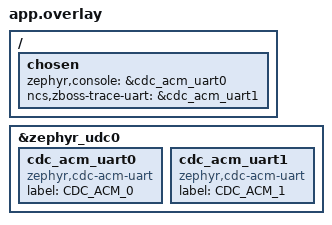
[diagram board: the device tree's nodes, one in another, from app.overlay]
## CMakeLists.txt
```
# SPDX-License-Identifier: Apache-2.0

cmake_minimum_required(VERSION 3.20.0)
find_package(Zephyr REQUIRED HINTS $ENV{ZEPHYR_BASE})
project(ultrasound-distance)

target_sources(app PRIVATE
    # Application sources
    src/main.c)

target_include_directories(app PRIVATE include)
```

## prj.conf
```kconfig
#
# Copyright (c) 2021 Nordic Semiconductor ASA
#
# SPDX-License-Identifier: LicenseRef-Nordic-5-Clause
#

#CONFIG_NCS_SAMPLES_DEFAULTS=y
#CONFIG_UART_INTERRUPT_DRIVEN=y
# Enable DK LED and Buttons library
#CONFIG_DK_LIBRARY=y


#
# Zigbee
#

CONFIG_ZIGBEE=y
CONFIG_ZIGBEE_APP_UTILS=y
CONFIG_ZIGBEE_ROLE_END_DEVICE=y

#
# Logging
#

#CONFIG_USB_DEVICE_PRODUCT="MyNRF52840Stick"
#CONFIG_USB_DEVICE_VID=4440

# PrintK

CONFIG_SERIAL=y
CONFIG_USB_DEVICE_STACK=y
CONFIG_USB_CDC_ACM=y
CONFIG_USB_CDC_ACM_LOG_LEVEL_DBG=y
CONFIG_CONSOLE=y
CONFIG_UART_CONSOLE=y                  # use one UART for console
CONFIG_UART_LINE_CTRL=y                # control serial: baud rate, etc.
CONFIG_PRINTK=y                        # send printk to console

# Traceback

#CONFIG_UART_ON_DEV_NAME="CDC_ACM_0"

#CONFIG_LOG=y                           # compile in LOG_x calls
#CONFIG_LOG_BACKEND_UART=y              # use UART for LOG_x
#CONFIG_LOG_BACKEND_SHOW_COLOR=n

#CONFIG_ZIGBEE_ENABLE_TRACES=y
#CONFIG_ZBOSS_TRACE_UART_LOGGING=y
#CONFIG_ZBOSS_TRACE_USB_CDC_LOGGING=y
#CONFIG_ZBOSS_TRACE_LOG_LEVEL_DBG=y
#CONFIG_USB_COMPOSITE_DEVICE=y

#CONFIG_LOG=y
#CONFIG_ZIGBEE_ENABLE_TRACES=y             # enable builtin traces lib
#CONFIG_ZBOSS_TRACE_UART_LOGGING=y
#CONFIG_ZIGBEE_LOGGER_EP_LOG_LEVEL_DBG=y
#CONFIG_ZBOSS_TRACE_MASK=0x0003
#CONFIG_ZBOSS_TRACE_USB_CDC_LOGGING=y
#CONFIG_ZBOSS_TRACE_LOG_LEVEL_OFF=n
#CONFIG_ZBOSS_TRACE_LOG_LEVEL_DBG=y
#CONFIG_USB_COMPOSITE_DEVICE=y             # multiple USB for serials
#CONFIG_ZBOSS_TRACE_HEXDUMP_LOGGING=y
#CONFIG_ZBOSS_TRACE_LOGGER_DEVICE_NAME="CDC_ACM_1"

# https://devzone.nordicsemi.com/f/nordic-q-a/85395/nrf52840-dongle-zephyr-logging-cdc-acm-composite
#CONFIG_LOG=y
#CONFIG_LOG_BACKEND_UART=y

#
# Other from upstream
#

CONFIG_GPIO=y
CONFIG_HEAP_MEM_POOL_SIZE=2048
CONFIG_MAIN_THREAD_PRIORITY=7


# This example requires more workqueue stack
CONFIG_SYSTEM_WORKQUEUE_STACK_SIZE=2048

# Enable nRF ECB driver
CONFIG_CRYPTO=y
CONFIG_CRYPTO_NRF_ECB=y
CONFIG_CRYPTO_INIT_PRIORITY=80

# Networking
CONFIG_NET_IPV6_MLD=n
CONFIG_NET_IPV6_NBR_CACHE=n
CONFIG_NET_IPV6_RA_RDNSS=n
CONFIG_NET_IP_ADDR_CHECK=n
CONFIG_NET_UDP=n
```

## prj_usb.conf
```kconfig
CONFIG_ZIGBEE_UART_DEVICE_NAME="CDC_ACM_0"
CONFIG_ZIGBEE_UART_SUPPORTS_FLOW_CONTROL=y
CONFIG_USB_COMPOSITE_DEVICE=y

CONFIG_USB_DEVICE_STACK=y
CONFIG_USB_DEVICE_REMOTE_WAKEUP=n
CONFIG_USB_DEVICE_PRODUCT="Zigbee NCP"
CONFIG_USB_CDC_ACM=y
CONFIG_UART_LINE_CTRL=y

CONFIG_ZIGBEE=y

CONFIG_ZIGBEE_LIBRARY_NCP_DEV=y

CONFIG_ZIGBEE_HAVE_SERIAL=y
CONFIG_ZIGBEE_HAVE_ASYNC_SERIAL=y
CONFIG_ZIGBEE_UART_RX_BUF_LEN=256
CONFIG_ZIGBEE_UART_TX_TIMEOUT=1000
CONFIG_ZIGBEE_UART_RX_TIMEOUT=1000

CONFIG_ZIGBEE_USE_LEDS=y
CONFIG_ZIGBEE_TIME_KTIMER=y
CONFIG_ZIGBEE_ROLE_COORDINATOR=y

CONFIG_HEAP_MEM_POOL_SIZE=2048

CONFIG_MAIN_THREAD_PRIORITY=7

CONFIG_SYSTEM_WORKQUEUE_STACK_SIZE=2048

# NetworkingCONFIG_NET_IPV6_MLD=n
CONFIG_NET_IPV6_NBR_CACHE=n
CONFIG_NET_IPV6_RA_RDNSS=n
CONFIG_NET_IP_ADDR_CHECK=n
CONFIG_NET_UDP=n

CONFIG_LOG=y
CONFIG_LOG_DEFAULT_LEVEL=3
CONFIG_CONSOLE=y
CONFIG_UART_CONSOLE=y
CONFIG_LOG_BACKEND_UART=y

CONFIG_ASSERT=nCONFIG_ASSERT_NO_COND_INFO=n
CONFIG_ASSERT_NO_MSG_INFO=n
```

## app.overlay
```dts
/*
 * Copyright (c) 2022 Brandon Satrom
 *
 * SPDX-License-Identifier: Apache-2.0
 */

/ {
	chosen {
		zephyr,console = &cdc_acm_uart0;
		ncs,zboss-trace-uart = &cdc_acm_uart1;
	};
};

&zephyr_udc0 {
	cdc_acm_uart0: cdc_acm_uart0 {
		compatible = "zephyr,cdc-acm-uart";
		label = "CDC_ACM_0";
	};
	cdc_acm_uart1: cdc_acm_uart1 {
		compatible = "zephyr,cdc-acm-uart";
		label = "CDC_ACM_1";
	};
};
```

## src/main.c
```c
/*
 * Written by Brandon Satrom.
 *
 * Copyright (c) 2022 Blues Inc. MIT License. Use of this source code is
 * governed by licenses granted by the copyright holder including that found in
 * the LICENSE file.
 */

#include <sys/printk.h>
#include <sys/util.h>
#include <string.h>

#include <usb/usb_device.h>
#include <drivers/uart.h>

#include <zephyr/drivers/gpio.h>
#include <zephyr/logging/log.h>
#include <zephyr/settings/settings.h>

#include <zboss_api.h>
#include <zboss_api_addons.h>
#include <zigbee/zigbee_app_utils.h>
#include <zigbee/zigbee_error_handler.h>
#include <zigbee/zigbee_zcl_scenes.h>
#include <zb_nrf_platform.h>

#include "my_zb_zcl_analog_input.h"
#include "zb_ultrasound_distance.h"

// Edited remotely

LOG_MODULE_REGISTER(zigmee, LOG_LEVEL_DBG);

/*
 * Ensure that an overlay for USB serial has been defined.
 */
BUILD_ASSERT(DT_NODE_HAS_COMPAT(DT_CHOSEN(zephyr_console), zephyr_cdc_acm_uart),
	    "Console device is not ACM CDC UART device");

/*
 * Defines
 */

#define ZB_ZCL_MIN_REPORTING_INTERVAL_DEFAULT 0x05
#define ZIGBEE_NETWORK_STATE_LED 0
#define LED0 DT_ALIAS(led0)
/* Device endpoint, used to receive ZCL commands. */
#define ULTRASOUND_DISTANCE_ENDPOINT 1
static const struct gpio_dt_spec led = GPIO_DT_SPEC_GET(LED0, gpios);

/* ESP tutorial */
#define IEEE_CHANNEL_MASK (1l << 13)  // channel 13
#define ERASE_PERSISTENT_CONFIG ZB_TRUE
/* END ESP tutorial */

/*
 * Zigbee setup
 */

/* Main application customizable context.
 * Stores all settings and static values.
 */

// ===== Declare Structures =====

typedef struct {
	zb_uint32_t present_value;
	zb_bool_t out_of_service;
	zb_uint8_t status_flags;
} my_zb_zcl_analog_input_basic_attrs;

typedef struct {
	zb_zcl_basic_attrs_ext_t basic_attr;
	zb_zcl_identify_attrs_t identify_attr;
	zb_zcl_scenes_attrs_t scenes_attr;
	zb_zcl_groups_attrs_t groups_attr;
	my_zb_zcl_analog_input_basic_attrs analog_input_attr;
} zb_device_ctx;

static zb_device_ctx dev_ctx;

// ===== Declare Attributes =====

ZB_ZCL_DECLARE_BASIC_ATTRIB_LIST_EXT(basic_attr_list,
	&dev_ctx.basic_attr.zcl_version,
	&dev_ctx.basic_attr.app_version,
	&dev_ctx.basic_attr.stack_version,
	&dev_ctx.basic_attr.hw_version,
	&dev_ctx.basic_attr.mf_name,
	&dev_ctx.basic_attr.model_id,
	&dev_ctx.basic_attr.date_code,
	&dev_ctx.basic_attr.location_id,
	&dev_ctx.basic_attr.ph_env,
	&dev_ctx.basic_attr.sw_ver,
	&dev_ctx.basic_attr.power_source);

ZB_ZCL_DECLARE_IDENTIFY_ATTRIB_LIST(identify_attr_list,
	&dev_ctx.identify_attr.identify_time);

ZB_ZCL_DECLARE_GROUPS_ATTRIB_LIST(groups_attr_list,
	&dev_ctx.groups_attr.name_support);

ZB_ZCL_DECLARE_SCENES_ATTRIB_LIST(scenes_attr_list,
	&dev_ctx.scenes_attr.scene_count,
	&dev_ctx.scenes_attr.current_scene,
	&dev_ctx.scenes_attr.current_group,
	&dev_ctx.scenes_attr.scene_valid,
	&dev_ctx.scenes_attr.name_support);
	
ZB_ZCL_DECLARE_ANALOG_INPUT_ATTRIB_LIST(analog_input_attr_list,
    &dev_ctx.analog_input_attr.out_of_service,
    &dev_ctx.analog_input_attr.present_value,
    &dev_ctx.analog_input_attr.status_flags);

// ===== Declare Device =====

ZB_DECLARE_ULTRASOUND_DISTANCE_CLUSTER_LIST(ultrasound_distance_clusters,
	basic_attr_list,
	identify_attr_list,
    groups_attr_list,
    scenes_attr_list,
	analog_input_attr_list);

ZB_DECLARE_ULTRASOUND_DISTANCE_EP(
	ultrasound_distance_ep,
	ULTRASOUND_DISTANCE_ENDPOINT,
	ultrasound_distance_clusters);
	

ZBOSS_DECLARE_DEVICE_CTX_1_EP(ultrasound_distance_ctx,
	ultrasound_distance_ep);

// ===== Business functions =====

static void init_zigbee_cluster_attributes() {
	// "Basic" cluster attributes
	dev_ctx.basic_attr.zcl_version = ZB_ZCL_VERSION;
	dev_ctx.basic_attr.power_source = ZB_ZCL_BASIC_POWER_SOURCE_BATTERY;
	ZB_ZCL_SET_STRING_VAL(
		dev_ctx.basic_attr.mf_name,
		"Tanel Liiv",
		ZB_ZCL_STRING_CONST_SIZE("Tanel Liiv"));
	ZB_ZCL_SET_STRING_VAL(
		dev_ctx.basic_attr.model_id,
		"tliiv.ultrasound_distance",
		ZB_ZCL_STRING_CONST_SIZE("tliiv.ultrasound_distance"));

	// "Identify" cluster attributes
	dev_ctx.identify_attr.identify_time = ZB_ZCL_IDENTIFY_IDENTIFY_TIME_DEFAULT_VALUE;

	// Groups cluster attribs
	dev_ctx.groups_attr.name_support = 0;

	// Scenes cluster attribs
	dev_ctx.scenes_attr.name_support = 0;

	// Distance attributes
	dev_ctx.analog_input_attr.out_of_service = false;
	dev_ctx.analog_input_attr.present_value = 123.0;
	dev_ctx.analog_input_attr.status_flags = 0;
}

static void start_identifying() {
	if (ZB_JOINED()) {
		zb_ret_t zb_err_code = zb_bdb_finding_binding_target(
			ULTRASOUND_DISTANCE_ENDPOINT
		);	
		if (zb_err_code == RET_OK) {
			printk("Entered identify mode!\n");
		} else if (zb_err_code == RET_INVALID_STATE) {
			printk("Invalid state!\n");	
		} else {
			printk("Umm, something else\n");
		}
	} else {
		printk("Device not in a network, cannot identify\n");
	}
}

/*
 * @brief Function to handle identify notification events on the first endpoint.
 * @param  bufid  Unused parameter, required by ZBOSS scheduler API.
 */
static void identify_cb(zb_bufid_t bufid)
{
	printk("IdentityCB!\n");
	k_sleep(K_MSEC(1000));

	zb_ret_t zb_err_code;
	if (bufid) {
		// Schedule a self-scheduling function that will toggle the LED
		//ZB_SCHEDULE_APP_CALLBACK(toggle_identify_led, bufid);
	} else {
		// Cancel the toggling function alarm and turn off LED
		//zb_err_code = ZB_SCHEDULE_APP_ALARM_CANCEL(toggle_identify_led, ZB_ALARM_ANY_PARAM);
		ZVUNUSED(zb_err_code);
		//dk_set_led(IDENTIFY_LED, 0);
	}
}

static void zcl_device_cb(zb_bufid_t bufid) {
	printk("DEVICE_DB\n");
}

void zboss_signal_handler(zb_bufid_t bufid) {
    ZB_ERROR_CHECK(zigbee_default_signal_handler(bufid));
    if (bufid) {
        zb_buf_free(bufid);
    }
}

void zboss_signal_handler2(zb_bufid_t bufid) {

	// update network status led
	//zigbee_led_status_update(bufid, ZIGBEE_NETWORK_STATE_LED);

	// No application-specific behavior is required. Call default signal handler.
	//zigbee_default_signal_handler(bufid);
	
	zb_zdo_app_signal_hdr_t *hdr = NULL;
	zb_zdo_app_signal_type_t sig = zb_get_app_signal(bufid, &hdr);
	zb_ret_t              status = ZB_GET_APP_SIGNAL_STATUS(bufid);

	if (sig != ZB_COMMON_SIGNAL_CAN_SLEEP) {
		printk("ZBOSS_SIGNAL_HANDLER signal %d status %d\n", sig, status);
	}

	switch (sig){
    case ZB_ZDO_SIGNAL_PRODUCTION_CONFIG_READY:
        printk("App config loaded: %d\n", status == RET_OK);
        break;
	case ZB_ZDO_SIGNAL_SKIP_STARTUP:
		printk("Zigbee stack init: %d\n", status == RET_OK);
		bdb_start_top_level_commissioning(ZB_BDB_INITIALIZATION);
		break;
	case ZB_BDB_SIGNAL_DEVICE_FIRST_START:
        printk("Started first time after NVRAM erase: %d\n", status == RET_OK);
		if (status == RET_OK) {
			printk("Start network steering\n");
			bdb_start_top_level_commissioning(ZB_BDB_NETWORK_STEERING);
		} else {
			printk("Failed to init Zigbee stack\n");
		}
		break;
	case ZB_BDB_SIGNAL_STEERING:
        printk("Network steering: %d\n", status == RET_OK);
		if (status == RET_OK) {
			printk("Joined network!\n");
		} else {
			printk("Steering unsuccessful :(\n");
			ZB_SCHEDULE_APP_ALARM((zb_callback_t) bdb_start_top_level_commissioning,
					ZB_BDB_NETWORK_STEERING, ZB_TIME_ONE_SECOND);
		}
		break;
	case ZB_BDB_SIGNAL_DEVICE_REBOOT:
		printk("Re/Joined a network using NVRAM contents\n");
        zb_ret_t resp = zb_zcl_start_attr_reporting(
                ULTRASOUND_DISTANCE_ENDPOINT,
                ZB_ZCL_CLUSTER_ID_ANALOG_INPUT,
                ZB_ZCL_CLUSTER_SERVER_ROLE,
                ZB_ZCL_ATTR_ANALOG_INPUT_PRESENT_VALUE_ID);
        if (resp == RET_OK) {
            printk("Reporting started!\n");
        } else {
            printk("Reporting failed to start\n");
        }
		break;
	case ZB_COMMON_SIGNAL_CAN_SLEEP:
		break;
	default:
		// print the unknown signal value
		printk("Unhandled signal: %d\n", sig);
		break;
	}

	k_sleep(K_MSEC(333));

	/* All callbacks should either reuse or free passed buffers.
	 * If bufid == 0, the buffer is invalid (not passed).
	 */
	if (bufid) {
		zb_buf_free(bufid);
	}
}

/*
 * None Zigbee stuff
 */

void zigbee_setup() {
	// -- Zigbee Stack
	
	/*ZB_INIT("avalanche_duck");
	zb_set_network_ed_role(IEEE_CHANNEL_MASK);
	zb_set_nvram_erase_at_start(ERASE_PERSISTENT_CONFIG);
	zb_set_ed_timeout(ED_AGING_TIMEOUT_64MIN);
	zb_set_keepalive_timeout(ZB_MILLISECONDS_TO_BEACON_INTERVAL(3000));*/

	zb_set_network_ed_role(ZB_TRANSCEIVER_ALL_CHANNELS_MASK);
	// -- HW Related

	ZB_ZCL_REGISTER_DEVICE_CB(zcl_device_cb);
	ZB_AF_REGISTER_DEVICE_CTX(&ultrasound_distance_ctx);

	// set all initial values
	init_zigbee_cluster_attributes();

	ZB_AF_SET_IDENTIFY_NOTIFICATION_HANDLER(ULTRASOUND_DISTANCE_ENDPOINT, identify_cb);
}

static zb_uint32_t i = 0;
void measure_distance() {
    //if (!system_param.connected) return;
    // -- Measure distance
    printk("Measure distance %d\n", ++i);
    // integer to bytes
    float distance = (float)i;
    zb_uint8_t *bytes = (zb_uint8_t *) &distance;

    zb_zcl_status_t result = zb_zcl_set_attr_val(
        ULTRASOUND_DISTANCE_ENDPOINT,
        ZB_ZCL_CLUSTER_ID_ANALOG_INPUT,
        ZB_ZCL_CLUSTER_SERVER_ROLE,
        ZB_ZCL_ATTR_ANALOG_INPUT_PRESENT_VALUE_ID,
        bytes,
        ZB_FALSE
    );
    if (result != ZB_ZCL_STATUS_SUCCESS) {
        printk("Failed to set attribute value: %d\n", result);
    }
    zb_zcl_mark_attr_for_reporting(
        ULTRASOUND_DISTANCE_ENDPOINT,
        ZB_ZCL_CLUSTER_ID_ANALOG_INPUT,
        ZB_ZCL_CLUSTER_SERVER_ROLE,
        ZB_ZCL_ATTR_ANALOG_INPUT_PRESENT_VALUE_ID
    );
    /*
    zb_bool_t resp = zcl_is_attr_reported(
            ULTRASOUND_DISTANCE_ENDPOINT,
            ZB_ZCL_CLUSTER_ID_ANALOG_INPUT,
            ZB_ZCL_CLUSTER_SERVER_ROLE,
            ZB_ZCL_ATTR_ANALOG_INPUT_PRESENT_VALUE_ID);
    if (resp) {
        printk("Attribute is reported\n");
    } else {
        printk("Attribute is not reported\n");
    }*/

}

void start_reporting() {
    zb_ret_t resp = zb_zcl_start_attr_reporting(
            ULTRASOUND_DISTANCE_ENDPOINT,
            ZB_ZCL_CLUSTER_ID_ANALOG_INPUT,
            ZB_ZCL_CLUSTER_SERVER_ROLE,
            ZB_ZCL_ATTR_ANALOG_INPUT_PRESENT_VALUE_ID);

    if (resp == RET_OK) {
        printk("Reporting started!\n");
    } else {
        printk("Reporting failed to start\n");
    }
}

void main(void)
{
	gpio_pin_configure_dt(&led, GPIO_OUTPUT_ACTIVE);

	/* Set ZigBee stack logging level and traffic dump subsystem. */
	//ZB_SET_TRACE_LEVEL(0b111111);
	//ZB_SET_TRACE_MASK(ZIGBEE_TRACE_MASK);
	//ZB_SET_TRAF_DUMP_OFF();

	// --- Configure USB Serial for Console output ---


	const struct device *usb_dev = DEVICE_DT_GET(DT_CHOSEN(zephyr_console));
	uint32_t dtr = 0;

	if (usb_enable(NULL)) {
		return;
	}

	uint32_t i = 0;
	while (!dtr) {
		uart_line_ctrl_get(usb_dev, UART_LINE_CTRL_DTR, &dtr);
		gpio_pin_set_raw(led.port, led.pin, i++ % 10 > 0 ? 0 : 1);
		k_sleep(K_MSEC(200));
	}

	//zcl_scenes_init();
	/*int err = settings_subsys_init();
	if (err) {
		printk("Failed to init settings!\n");
	}*/

	// --- Start ---

	printk("=| Welcome to Avalanche Duck NRF52840 Zigbee Endpoint v0.1|=\n");
	LOG_ERR("HI LOG WORKS!\n");

	zigbee_setup();
	zigbee_enable();
    start_reporting();

	i = 1;
	while (1) {
		gpio_pin_set_raw(led.port, led.pin, i % 2);
        printk("Main loop %d\n", i++);
		if (i % 10 == 0) {
            //zboss_main_loop_iteration();
            printk("measuring\n");
            measure_distance();
		}
		k_sleep(K_MSEC(1000));
	}
}
```

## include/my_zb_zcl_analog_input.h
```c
/*
 * ZBOSS Zigbee 3.0
 *
 * Copyright (c) 2012-2022 DSR Corporation, Denver CO, USA.
 * www.dsr-zboss.com
 * www.dsr-corporation.com
 * All rights reserved.
 *
 *
 * Use in source and binary forms, redistribution in binary form only, with
 * or without modification, are permitted provided that the following conditions
 * are met:
 *
 * 1. Redistributions in binary form, except as embedded into a Nordic
 *    Semiconductor ASA integrated circuit in a product or a software update for
 *    such product, must reproduce the above copyright notice, this list of
 *    conditions and the following disclaimer in the documentation and/or other
 *    materials provided with the distribution.
 *
 * 2. Neither the name of Nordic Semiconductor ASA nor the names of its
 *    contributors may be used to endorse or promote products derived from this
 *    software without specific prior written permission.
 *
 * 3. This software, with or without modification, must only be used with a Nordic
 *    Semiconductor ASA integrated circuit.
 *
 * 4. Any software provided in binary form under this license must not be reverse
 *    engineered, decompiled, modified and/or disassembled.
 *
 * THIS SOFTWARE IS PROVIDED BY NORDIC SEMICONDUCTOR ASA "AS IS" AND ANY EXPRESS OR
 * IMPLIED WARRANTIES, INCLUDING, BUT NOT LIMITED TO, THE IMPLIED WARRANTIES OF
 * MERCHANTABILITY, NONINFRINGEMENT, AND FITNESS FOR A PARTICULAR PURPOSE ARE
 * DISCLAIMED. IN NO EVENT SHALL NORDIC SEMICONDUCTOR ASA OR CONTRIBUTORS BE LIABLE
 * FOR ANY DIRECT, INDIRECT, INCIDENTAL, SPECIAL, EXEMPLARY, OR CONSEQUENTIAL
 * DAMAGES (INCLUDING, BUT NOT LIMITED TO, PROCUREMENT OF SUBSTITUTE GOODS OR
 * SERVICES; LOSS OF USE, DATA, OR PROFITS; OR BUSINESS INTERRUPTION) HOWEVER
 * CAUSED AND ON ANY THEORY OF LIABILITY, WHETHER IN CONTRACT, STRICT LIABILITY, OR
 * TORT (INCLUDING NEGLIGENCE OR OTHERWISE) ARISING IN ANY WAY OUT OF THE USE OF
 * THIS SOFTWARE, EVEN IF ADVISED OF THE POSSIBILITY OF SUCH DAMAGE.
 */
/* PURPOSE: (Incomplete!) Analog Output cluster
 * By Tanel Liiv
*/

#ifndef ZB_ZCL_ANALOG_INPUT_H
#define ZB_ZCL_ANALOG_INPUT_H 1

#include "zcl/zb_zcl_common.h"
#include "zcl/zb_zcl_commands.h"

enum zb_zcl_analog_input_attr_e
{
  /** The Description attribute, of type Character string, MAY be used to hold a
   *  description of the usage of the input, output or value, as appropriate
   *  to the cluster. */
  ZB_ZCL_ATTR_ANALOG_INPUT_DESCRIPTION_ID               = 0x001C,
  /** This attribute, of type Character string, MAY be used to hold a human readable
   *  description of the INACTIVE state of a binary PresentValue. */
  ZB_ZCL_ATTR_ANALOG_INPUT_INACTIVE_TEXT_ID             = 0x002E,

  /** @brief OutOfService attribute */
  ZB_ZCL_ATTR_ANALOG_INPUT_OUT_OF_SERVICE_ID            = 0x0051,

  /** @brief PresentValue attribute */
  ZB_ZCL_ATTR_ANALOG_INPUT_PRESENT_VALUE_ID             = 0x0055,

  /** @brief StatusFlag attribute */
  ZB_ZCL_ATTR_ANALOG_INPUT_STATUS_FLAG_ID               = 0x006F,
};

/**
 *  @brief StatusFlag attribute values.
 *  @see ZCL spec 3.14.10.3.
 */
enum zb_zcl_analog_input_status_flag_value_e
{
  ZB_ZCL_ANALOG_INPUT_STATUS_FLAG_NORMAL    = 0x00,       /**< Normal (default) state. */
  ZB_ZCL_ANALOG_INPUT_STATUS_FLAG_IN_ALARM  = 0x01,       /**< In alarm bit. */
  ZB_ZCL_ANALOG_INPUT_STATUS_FLAG_FAULT     = 0x02,       /**< Fault bit. */
  ZB_ZCL_ANALOG_INPUT_STATUS_FLAG_OVERRIDEN = 0x04,       /**< Overridden bit. */
  ZB_ZCL_ANALOG_INPUT_STATUS_FLAG_OUT_OF_SERVICE = 0x08,  /**< Out of service bit. */
};

/** @brief Default value for Binary Input cluster revision global attribute */
//#define ZB_ZCL_BINARY_INPUT_CLUSTER_REVISION_DEFAULT ((zb_uint16_t)0x0001u)
#define ZB_ZCL_ANALOG_INPUT_CLUSTER_REVISION_DEFAULT ((zb_uint16_t)0x0001u)

/** @brief Default value for ActiveText attribute */
#define ZB_ZCL_BINARY_INPUT_ACTIVE_TEXT_DEFAULT_VALUE {0}

/** @brief Default value for Description attribute */
#define ZB_ZCL_BINARY_INPUT_DESCRIPTION_DEFAULT_VALUE {0}

/** @brief Default value for InactiveText attribute */
#define ZB_ZCL_BINARY_INPUT_INACTIVE_TEXT_DEFAULT_VALUE {0}

/*! @brief OutOfService attribute default value */
#define ZB_ZCL_ANALOG_INPUT_OUT_OF_SERVICE_DEFAULT_VALUE ZB_FALSE

/** @brief Default value for Polarity attribute */
#define ZB_ZCL_BINARY_INPUT_POLARITY_DEFAULT_VALUE ((zb_uint8_t)0)

/** @brief Default value for Reliability attribute */
#define ZB_ZCL_BINARY_INPUT_RELIABILITY_DEFAULT_VALUE ((zb_uint8_t)0x00)

/*! @brief StatusFlag attribute default value */
#define ZB_ZCL_BINARY_INPUT_STATUS_FLAG_DEFAULT_VALUE ZB_ZCL_BINARY_INPUT_STATUS_FLAG_NORMAL

/*! @brief StatusFlag attribute minimum value */
#define ZB_ZCL_BINARY_INPUT_STATUS_FLAG_MIN_VALUE 0

/*! @brief StatusFlag attribute maximum value */
#define ZB_ZCL_BINARY_INPUT_STATUS_FLAG_MAX_VALUE 0x0F

/** @brief Declare attribute list for Binary Input cluster
    @param attr_list - attribute list name
    @param out_of_service - pointer to variable to store OutOfService attribute value
    @param present_value -  pointer to variable to store PresentValue attribute value
    @param status_flag -  pointer to variable to store StatusFlag attribute value
*/
#define ZB_ZCL_DECLARE_ANALOG_INPUT_ATTRIB_LIST(                                     \
    attr_list, out_of_service, present_value, status_flag)                           \
  ZB_ZCL_START_DECLARE_ATTRIB_LIST_CLUSTER_REVISION(attr_list, ZB_ZCL_ANALOG_INPUT)  \
  ZB_ZCL_SET_ATTR_DESC(ZB_ZCL_ATTR_ANALOG_INPUT_OUT_OF_SERVICE_ID, (out_of_service)) \
  ZB_ZCL_SET_ATTR_DESC(ZB_ZCL_ATTR_ANALOG_INPUT_PRESENT_VALUE_ID, (present_value))   \
  ZB_ZCL_SET_ATTR_DESC(ZB_ZCL_ATTR_ANALOG_INPUT_STATUS_FLAG_ID, (status_flag))       \
  ZB_ZCL_FINISH_DECLARE_ATTRIB_LIST

/*! @} */ /* Binary Input cluster attributes */

/*! @name Binary input attribute value manipulation API
    @{
*/

/** @brief Set normal operating mode
    @param ep - endpoint number
*/
/*
#define ZB_ZCL_BINARY_INPUT_SET_NORMAL_MODE(ep)                           \
{                                                                         \
  zb_uint8_t val;                                                         \
                                                                          \
  val = ZB_FALSE;                                                         \
  ZB_ZCL_SET_ATTRIBUTE(ep, ZB_ZCL_CLUSTER_ID_BINARY_INPUT,                \
                       ZB_ZCL_CLUSTER_SERVER_ROLE,                        \
                       ZB_ZCL_ATTR_BINARY_INPUT_OUT_OF_SERVICE_ID,        \
                       &val, ZB_FALSE);                                   \
                                                                          \
  val = ZB_ZCL_BINARY_INPUT_STATUS_FLAG_NORMAL;                           \
  ZB_ZCL_SET_ATTRIBUTE(ep, ZB_ZCL_CLUSTER_ID_BINARY_INPUT,                \
                       ZB_ZCL_CLUSTER_SERVER_ROLE,                        \
                       ZB_ZCL_ATTR_BINARY_INPUT_STATUS_FLAG_ID,           \
                       &val, ZB_FALSE);                                   \
}*/

/** @brief Set Out of service operating mode
    @param ep - endpoint number
*/
/*
#define ZB_ZCL_BINARY_INPUT_SET_OUT_OF_SERVICE(ep)                                          \
{                                                                                           \
  zb_zcl_attr_t *attr_desc;                                                                 \
  zb_uint8_t val;                                                                           \
                                                                                            \
  val = ZB_TRUE;                                                                            \
  ZB_ZCL_SET_ATTRIBUTE(ep, ZB_ZCL_CLUSTER_ID_BINARY_INPUT,                                  \
                       ZB_ZCL_CLUSTER_SERVER_ROLE,                                          \
                       ZB_ZCL_ATTR_BINARY_INPUT_OUT_OF_SERVICE_ID,                          \
                       &val, ZB_FALSE);                                                     \
                                                                                            \
  attr_desc = zb_zcl_get_attr_desc_a(ep, ZB_ZCL_CLUSTER_ID_BINARY_INPUT,                    \
                                     ZB_ZCL_CLUSTER_SERVER_ROLE,        \
                                     ZB_ZCL_ATTR_BINARY_INPUT_STATUS_FLAG_ID); \
  if (attr_desc)                                                                            \
  {                                                                                         \
    val = *(zb_uint8_t*)attr_desc->data_p | ZB_ZCL_BINARY_INPUT_STATUS_FLAG_OUT_OF_SERVICE; \
    ZB_ZCL_SET_ATTRIBUTE(ep, ZB_ZCL_CLUSTER_ID_BINARY_INPUT,                                \
                         ZB_ZCL_CLUSTER_SERVER_ROLE,                    \
                         ZB_ZCL_ATTR_BINARY_INPUT_STATUS_FLAG_ID,                           \
                         &val, ZB_FALSE);                                                   \
  }                                                                                         \
}*/

/** @brief Set overridden operating mode
   @param ep - endpoint number
*/
/*
#define ZB_ZCL_BINARY_INPUT_SET_OVERRIDEN_MODE(ep)                                     \
{                                                                                      \
  zb_zcl_attr_t *attr_desc;                                                            \
  zb_uint8_t val;                                                                      \
                                                                                       \
  attr_desc = zb_zcl_get_attr_desc_a(ep, ZB_ZCL_CLUSTER_ID_BINARY_INPUT,               \
                                     ZB_ZCL_CLUSTER_SERVER_ROLE,        \
                         ZB_ZCL_ATTR_BINARY_INPUT_STATUS_FLAG_ID);                     \
  if (attr_desc)                                                                       \
  {                                                                                    \
    val = *(zb_uint8_t*)attr_desc->data_p | ZB_ZCL_BINARY_INPUT_STATUS_FLAG_OVERRIDEN; \
    ZB_ZCL_SET_ATTRIBUTE(ep, ZB_ZCL_CLUSTER_ID_BINARY_INPUT,                           \
                         ZB_ZCL_CLUSTER_SERVER_ROLE,                    \
                         ZB_ZCL_ATTR_BINARY_INPUT_STATUS_FLAG_ID,                      \
                         &val, ZB_FALSE);                                              \
  }                                                                                    \
}*/

/*! @} */ /* Binary input cluster commands */

/** @cond internals_doc */
/** @name Binary Input cluster internals
    Internal structures for Binary Input cluster
    @{
*/

/* Optionally, access to this attribute may be changed to READ_WRITE */
#define ZB_SET_ATTR_DESCR_WITH_ZB_ZCL_ATTR_ANALOG_INPUT_OUT_OF_SERVICE_ID(data_ptr) \
{                                                                   \
  ZB_ZCL_ATTR_ANALOG_INPUT_OUT_OF_SERVICE_ID,                       \
  ZB_ZCL_ATTR_TYPE_BOOL,                                            \
  ZB_ZCL_ATTR_ACCESS_READ_ONLY | ZB_ZCL_ATTR_ACCESS_REPORTING, \
  (void*) data_ptr                                             \
}

/* Optionally, access to this attribute may be changed to READ_WRITE */
#define ZB_SET_ATTR_DESCR_WITH_ZB_ZCL_ATTR_ANALOG_INPUT_PRESENT_VALUE_ID(data_ptr) \
{                                                                   \
  ZB_ZCL_ATTR_ANALOG_INPUT_PRESENT_VALUE_ID,                        \
  ZB_ZCL_ATTR_TYPE_SINGLE,                                          \
  ZB_ZCL_ATTR_ACCESS_READ_ONLY | ZB_ZCL_ATTR_ACCESS_REPORTING, \
  (void*) data_ptr                                             \
}

#define ZB_SET_ATTR_DESCR_WITH_ZB_ZCL_ATTR_ANALOG_INPUT_STATUS_FLAG_ID(data_ptr) \
{                                                                   \
  ZB_ZCL_ATTR_ANALOG_INPUT_STATUS_FLAG_ID,                          \
  ZB_ZCL_ATTR_TYPE_8BITMAP,                                          \
  ZB_ZCL_ATTR_ACCESS_READ_ONLY | ZB_ZCL_ATTR_ACCESS_REPORTING,      \
  (void*) data_ptr                                             \
}

/*! Number of attributes mandatory for reporting in Analog Input cluster */
#define ZB_ZCL_ANALOG_INPUT_REPORT_ATTR_COUNT 3

/*! @}
 *  @endcond */ /* Binary Input cluster internals */


/*! @} */ /* ZCL Binary Input cluster definitions */

/** @endcond */ /* DOXYGEN_ZCL_SECTION */

void zb_zcl_analog_input_init_server(void);
// from zcl_binary_input.c

void zb_zcl_analog_input_init_server(void)
{
  zb_zcl_add_cluster_handlers(ZB_ZCL_CLUSTER_ID_ANALOG_INPUT,
			      ZB_ZCL_CLUSTER_SERVER_ROLE,
			      (zb_zcl_cluster_check_value_t)NULL,
			      (zb_zcl_cluster_write_attr_hook_t)NULL,
			      (zb_zcl_cluster_handler_t)NULL);
}

void zb_zcl_analog_input_init_client(void);
// from zcl_binary_input.c
void zb_zcl_analog_input_init_client(void)
{
  zb_zcl_add_cluster_handlers(ZB_ZCL_CLUSTER_ID_ANALOG_INPUT,
			      ZB_ZCL_CLUSTER_CLIENT_ROLE,
			      (zb_zcl_cluster_check_value_t)NULL,
			      (zb_zcl_cluster_write_attr_hook_t)NULL,
			      (zb_zcl_cluster_handler_t)NULL);
}

#define ZB_ZCL_CLUSTER_ID_ANALOG_INPUT_SERVER_ROLE_INIT zb_zcl_analog_input_init_server
#define ZB_ZCL_CLUSTER_ID_ANALOG_INPUT_CLIENT_ROLE_INIT zb_zcl_analog_input_init_client

#endif /* ZB_ZCL_BINARY_INPUT_H */
```

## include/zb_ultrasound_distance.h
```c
// sdk-nrf / zigbee / light_bulb / zb_dimmable_light.h
// https://github.com/nrfconnect/sdk-nrf/blob/main/samples/zigbee/light_bulb/include/zb_dimmable_light.h
// I excluded level control in last _EP

// -- Declare Cluster List

#define ZB_DECLARE_ULTRASOUND_DISTANCE_CLUSTER_LIST( \
	cluster_list_name, \
	basic_attr_list, \
	identify_attr_list, \
    groups_attr_list, \
    scenes_attr_list, \
	analog_input_attr_list) \
	zb_zcl_cluster_desc_t cluster_list_name[] = \
	{ \
		ZB_ZCL_CLUSTER_DESC( \
			ZB_ZCL_CLUSTER_ID_IDENTIFY, \
			ZB_ZCL_ARRAY_SIZE(identify_attr_list, zb_zcl_attr_t), \
			(identify_attr_list), \
			ZB_ZCL_CLUSTER_SERVER_ROLE, \
			ZB_ZCL_MANUF_CODE_INVALID \
		),\
		ZB_ZCL_CLUSTER_DESC( \
			ZB_ZCL_CLUSTER_ID_BASIC, \
			ZB_ZCL_ARRAY_SIZE(basic_attr_list, zb_zcl_attr_t), \
			(basic_attr_list), \
			ZB_ZCL_CLUSTER_SERVER_ROLE, \
			ZB_ZCL_MANUF_CODE_INVALID \
		),\
        ZB_ZCL_CLUSTER_DESC( \
            ZB_ZCL_CLUSTER_ID_GROUPS, \
            ZB_ZCL_ARRAY_SIZE(groups_attr_list, zb_zcl_attr_t), \
            (groups_attr_list), \
            ZB_ZCL_CLUSTER_SERVER_ROLE, \
            ZB_ZCL_MANUF_CODE_INVALID \
        ),\
        ZB_ZCL_CLUSTER_DESC( \
            ZB_ZCL_CLUSTER_ID_SCENES, \
            ZB_ZCL_ARRAY_SIZE(scenes_attr_list, zb_zcl_attr_t), \
            (scenes_attr_list), \
            ZB_ZCL_CLUSTER_SERVER_ROLE, \
            ZB_ZCL_MANUF_CODE_INVALID \
        ),\
		ZB_ZCL_CLUSTER_DESC( \
			ZB_ZCL_CLUSTER_ID_ANALOG_INPUT, \
			ZB_ZCL_ARRAY_SIZE(analog_input_attr_list, zb_zcl_attr_t), \
			(analog_input_attr_list), \
			ZB_ZCL_CLUSTER_SERVER_ROLE, \
			ZB_ZCL_MANUF_CODE_INVALID \
		),\
	}

// -- Declare Simple Descriptor for device

#define ZB_ULTRASOUND_DISTANCE_DEVICE_ID 0x0101
#define ZB_DEVICE_VER_ULTRASOUND_DISTANCE 1

#define ZB_ZCL_DECLARE_HA_ULTRASOUND_DISTANCE_SIMPLE_DESC( \
        ep_name, \
        ep_id, \
        in_clust_num, \
        out_clust_num) \
	ZB_DECLARE_SIMPLE_DESC(in_clust_num, out_clust_num); \
	ZB_AF_SIMPLE_DESC_TYPE(in_clust_num, out_clust_num) simple_desc_##ep_name = \
	{ \
		ep_id, \
		ZB_AF_HA_PROFILE_ID, \
		ZB_ULTRASOUND_DISTANCE_DEVICE_ID, \
		ZB_DEVICE_VER_ULTRASOUND_DISTANCE, \
		0, \
		in_clust_num, \
		out_clust_num, \
		{ \
			ZB_ZCL_CLUSTER_ID_BASIC, \
			ZB_ZCL_CLUSTER_ID_IDENTIFY, \
            ZB_ZCL_CLUSTER_ID_GROUPS, \
            ZB_ZCL_CLUSTER_ID_SCENES, \
			ZB_ZCL_CLUSTER_ID_ANALOG_INPUT, \
		} \
	}

// -- Declar Endpoint for device

#define ZB_ULTRASOUND_DISTANCE_IN_CLUSTER_NUM 5
#define ZB_ULTRASOUND_DISTANCE_OUT_CLUSTER_NUM 0
#define ZB_ULTRASOUND_DISTANCE_REPORT_ATTR_COUNT (ZB_ZCL_ANALOG_INPUT_REPORT_ATTR_COUNT)
#define ZB_ULTRASOUND_DISTANCE_CVC_ATTR_COUNT 1

#define ZB_DECLARE_ULTRASOUND_DISTANCE_EP(ep_name, ep_id, cluster_list) \
	ZB_ZCL_DECLARE_HA_ULTRASOUND_DISTANCE_SIMPLE_DESC( \
        ep_name, \
        ep_id, \
        ZB_ULTRASOUND_DISTANCE_IN_CLUSTER_NUM, \
        ZB_ULTRASOUND_DISTANCE_OUT_CLUSTER_NUM); \
    \
	ZBOSS_DEVICE_DECLARE_REPORTING_CTX( \
        reporting_info## ep_name, \
		ZB_ULTRASOUND_DISTANCE_REPORT_ATTR_COUNT); \
    \
	ZB_AF_DECLARE_ENDPOINT_DESC(ep_name, ep_id, ZB_AF_HA_PROFILE_ID, \
		0, \
		NULL, \
		ZB_ZCL_ARRAY_SIZE(cluster_list, zb_zcl_cluster_desc_t), \
		cluster_list, \
		(zb_af_simple_desc_1_1_t *)&simple_desc_## ep_name, \
		ZB_ULTRASOUND_DISTANCE_REPORT_ATTR_COUNT, \
		reporting_info## ep_name, \
		0, NULL);
			
```
